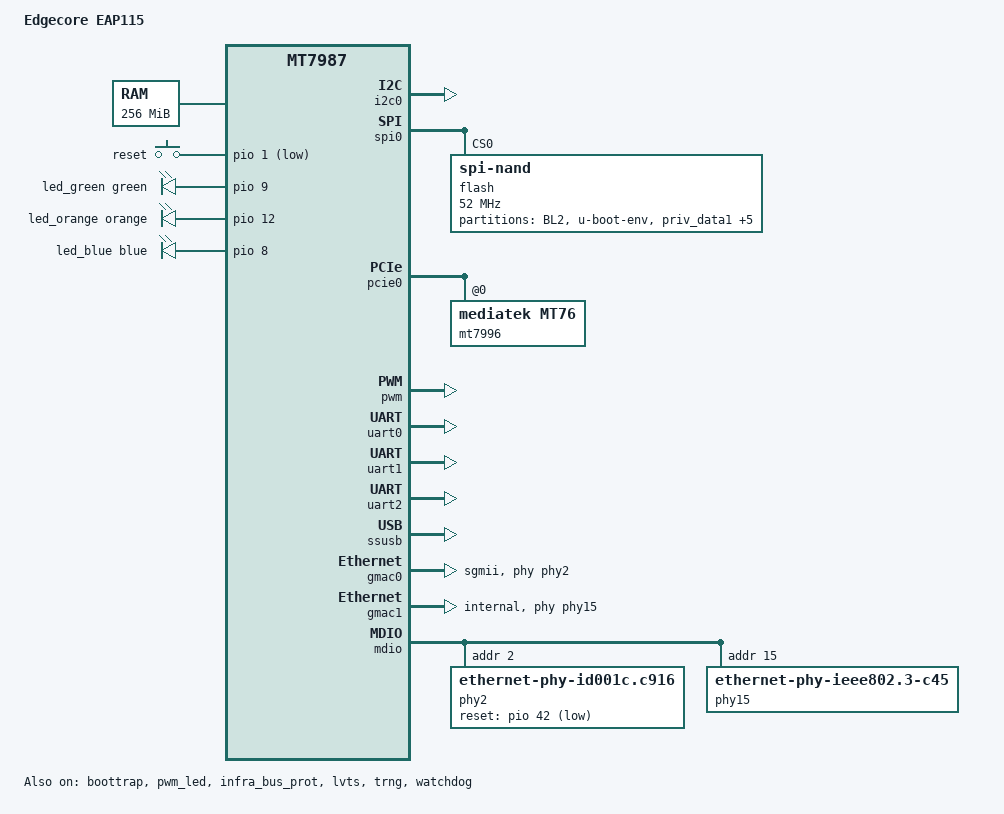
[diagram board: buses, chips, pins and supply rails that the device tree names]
// SPDX-License-Identifier: (GPL-2.0 OR MIT)
/*
 * Copyright (C) 2025 MediaTek Inc.
 * Author: Sam.Shih <sam.shih@mediatek.com>
 */

/dts-v1/;
#include <dt-bindings/leds/common.h>
#include "mt7987.dtsi"
#include "mt7987-pinctrl.dtsi"
#include "mt7987-netsys.dtsi"
#include <dt-bindings/input/input.h>

/* MT7987A RFB DTS for DT overlay-based device tree */
/ {
	model = "Edgecore EAP115";
	compatible = "edgecore,eap115";

	memory {
		reg = <0 0x40000000 0 0x10000000>;
	};

	aliases {
		serial0 = &uart0;
		led-boot = &led_green;
		led-failsafe = &led_green;
		led-running = &led_green;
		led-upgrade = &led_green;
		label-mac-device = &gmac1;
	};

	chosen {
		bootargs = "console=ttyS0,115200n1 loglevel=8  \
			    earlycon=uart8250,mmio32,0x11000000 \
			    pci=pcie_bus_perf";
	};

	gpio-keys {
		compatible = "gpio-keys";

		reset {
			label = "reset";
			linux,code = <KEY_RESTART>;
			gpios = <&pio 1 GPIO_ACTIVE_LOW>;
			debounce-interval = <10>;
		};
	};

	leds {
		compatible = "gpio-leds";

		led_green: led-green {
			gpios = <&pio 9 GPIO_ACTIVE_HIGH>;
			color = <LED_COLOR_ID_GREEN>;
			function = LED_FUNCTION_INDICATOR;
		};

		led_orange: led-orange {
			gpios = <&pio 12 GPIO_ACTIVE_HIGH>;
			color = <LED_COLOR_ID_ORANGE>;
			function = LED_FUNCTION_INDICATOR;
		};

		led_blue: led-blue {
			gpios = <&pio 8 GPIO_ACTIVE_HIGH>;
			color = <LED_COLOR_ID_BLUE>;
			function = LED_FUNCTION_INDICATOR;
		};
	};
};

&afe {
	pinctrl-names = "default";
	pinctrl-0 = <&pcm_pins>;
	status = "disabled";
};

&boottrap {
	status = "okay";
};

/* use pwm0 as fan: share with pwm_led/pwm_rgb */
&fan {
	pinctrl-names = "default";
	pinctrl-0 = <&pwm_pins>;
	pwms = <&pwm 0 50000 0>;
	status = "disabled";
};

/* use pwm0 as led: share with fan/pwm_rgb */
&pwm_led {
	pinctrl-names = "default";
	pinctrl-0 = <&pwm_pins>;
	status = "okay";

	led {
		pwms = <&pwm 0 50000 0>;
		max-brightness = <255>;
		active-low;
		linux,default-trigger = "default-on";
	};
};

/* use pwm0/1/2 as multicolor LED: share with fan/pwm_led */
&pwm_rgb {
	pinctrl-names = "default";
	pinctrl-0 = <&pwm_rgb_pins>;
	status = "disabled";

	multi-led {
		color = <LED_COLOR_ID_RGB>;
		function = LED_FUNCTION_INDICATOR;
		max-brightness = <255>;

		led-red {
			pwms = <&pwm 0 50000>;
			color = <LED_COLOR_ID_RED>;
		};

		led-green {
			pwms = <&pwm 1 50000>;
			color = <LED_COLOR_ID_GREEN>;
		};

		led-blue {
			pwms = <&pwm 2 50000>;
			color = <LED_COLOR_ID_BLUE>;
		};
	};
};

&i2c0 {
	pinctrl-names = "default";
	pinctrl-0 = <&i2c0_pins>;
	status = "okay";
};

&spi0 {
	pinctrl-names = "default";
	pinctrl-0 = <&spi0_flash_pins>;
	cs-gpios = <0>, <0>;
	#address-cells = <1>;
	#size-cells = <0>;
	status = "okay";

	flash@0 {
		#address-cells = <1>;
		#size-cells = <1>;
		compatible = "spi-nand";
		reg = <0>;
		spi-max-frequency = <52000000>;

		spi-cal-enable;
		spi-cal-mode = "read-data";
		spi-cal-datalen = <7>;
		spi-cal-data = /bits/ 8 <0x53 0x50 0x49 0x4E 0x41 0x4E 0x44>;
		spi-cal-addrlen = <5>;
		spi-cal-addr = /bits/ 32 <0x0 0x0 0x0 0x0 0x0>;

		spi-tx-bus-width = <4>;
		spi-rx-bus-width = <4>;
		mediatek,nmbm;
		mediatek,bmt-max-ratio = <1>;
		mediatek,bmt-max-reserved-blocks = <64>;

		partitions {
			compatible = "fixed-partitions";
			#address-cells = <1>;
			#size-cells = <1>;

			partition@0 {
				label = "BL2";
				reg = <0x00000 0x0100000>;
				read-only;
			};

			partition@100000 {
				label = "u-boot-env";
				reg = <0x0100000 0x0040000>;

			};

			partition@140000 {
				label = "priv_data1";
				reg = <0x140000 0x0020000>;
			};

			partition@160000 {
				label = "priv_data2";
				reg = <0x160000 0x0020000>;
			};

			factory: partition@180000 {
				label = "Factory";
				reg = <0x180000 0x0400000>;

				nvmem-layout {
					compatible = "fixed-layout";
					#address-cells = <1>;
					#size-cells = <1>;

					macaddr_wan: macaddr@2a {
						reg = <0x2a 0x6>;
					};

					macaddr_lan: macaddr@24 {
						reg = <0x24 0x6>;
					};
				};
			};

			partition@580000 {
				label = "FIP";
				reg = <0x580000 0x0200000>;
			};

			partition@780000 {
				label = "rootfs1";
				reg = <0x780000 0x3840000>;
			};

			partition@3fc0000 {
				label = "rootfs2";
				reg = <0x3fc0000 0x3840000>;
			};
		};
	};
};

&infra_bus_prot {
	status = "okay";
};

&lvts {
	status = "okay";
};

&pcie0 {
	pinctrl-names = "default";
	pinctrl-0 = <&pcie0_pins>;
	status = "okay";

	slot0: pcie@0,0 {
		reg = <0x0000 0 0 0 0>;

		mt7996@0,0 {
			compatible = "mediatek,mt76";
			reg = <0x0000 0 0 0 0>;
			device_type = "pci";
			mediatek,mtd-eeprom = <&factory 0x0>;
		};
	};
};

&pcie1 {
	pinctrl-names = "default";
	pinctrl-0 = <&pcie1_pins>;
	status = "disabled";
};

&pwm {
	status = "okay";
};

&trng {
	status = "okay";
};

&uart0 {
	status = "okay";
};

&uart1 {
	pinctrl-names = "default";
	pinctrl-0 = <&uart1_pins>;
	status = "okay";
};

&uart2 {
	pinctrl-names = "default";
	pinctrl-0 = <&uart2_pins>;
	status = "okay";
};

&watchdog {
	status = "okay";
};

&ssusb {
	status = "okay";
};

&eth {
	/delete-node/ mac@2;
};

&gmac0 {
	mac-type = "gdm";
	phy-mode = "sgmii";
	phy-handle = <&phy2>;
	nvmem-cells = <&macaddr_lan>;
	nvmem-cell-names = "mac-address";
	status = "okay";
};

&gmac1 {
	mac-type = "xgdm";
	phy-mode = "internal";
	phy-handle = <&phy15>;
	nvmem-cells = <&macaddr_wan>;
	nvmem-cell-names = "mac-address";
	status = "okay";
};

&mdio {
	phy2: phy@2 {
		compatible = "ethernet-phy-id001c.c916";
		reg = <2>;
		reset-gpio = <&pio 42 1>;
		reset-assert-us = <10000>;
		reset-deassert-us = <50000>;
		phy-mode = "sgmii";
		realtek,clkout-disable;
		realtek,aldps-enable;
	};

	phy15: phy@15 {
		pinctrl-names = "i2p5gbe-led";
		pinctrl-0 = <&i2p5gbe_led0_pins>;
		compatible = "ethernet-phy-ieee802.3-c45";
		reg = <15>;
		phy-mode = "internal";
	};
};
